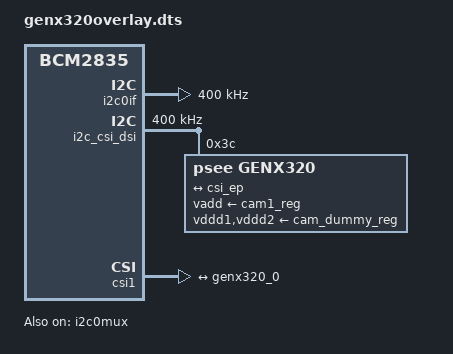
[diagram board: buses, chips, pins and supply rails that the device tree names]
// SPDX-License-Identifier: GPL-2.0-only
// Definitions for GenX320 camera module on VC I2C bus
/dts-v1/;
/plugin/;

// #include <dt-bindings/gpio/gpio.h>

/{
	compatible = "brcm,bcm2835";

	fragment@0 {
		target = <&i2c0if>;
		__overlay__ {
			status = "okay";
			clock-frequency = <400000>;
		};
	};

	clk_frag: fragment@1 {
		target = <&cam1_clk>;
		__overlay__ {
			status = "okay";
			clock-frequency = <20000000>;
		};
	};

	fragment@2 {
		target = <&i2c0mux>;
		__overlay__ {
			status = "okay";
		};
	};

	reg_frag: fragment@5 {
		target = <&cam1_reg>;
		cam_reg: __overlay__ {
			/* 500 ms lets CCAM5 on-module regulators stabilise before
			 * the driver's first I2C access. Increase via dtoverlay
			 * startup-delay-us=<N> if probe still times out. */
			startup-delay-us = <500000>;
		};
	};

	reg_alwayson_frag: fragment@99 {
		target = <&cam1_reg>;
		__dormant__ {
			regulator-always-on;
		};
	};

	i2c_frag: fragment@100 {
		target = <&i2c_csi_dsi>;
		__overlay__ {
			#address-cells = <1>;
			#size-cells = <0>;
			status = "okay";
			clock-frequency = <400000>;
			genx320: genx320@3c {
				compatible = "psee,genx320";
				reg = <0x3c>;
				status = "okay";

				clocks = <&cam1_clk>;
				clock-names = "inclk";

				/* Ask the Linux clock framework to program the RP1
				 * GPCLK to 20 MHz at probe time.  The Pi firmware
				 * already reads clock-frequency above before Linux
				 * boots, but on Pi 5 the RP1 clock driver can reset
				 * the rate unless assigned-clock-rates is also set. */
				assigned-clocks = <&cam1_clk>;
				assigned-clock-rates = <20000000>;

				vadd-supply = <&cam1_reg>;
				vddd1-supply = <&cam_dummy_reg>;
				vddd2-supply = <&cam_dummy_reg>;

				rotation = <180>;
				orientation = <2>;

				rstn-delay-ms = <385>;

				port {
					genx320_0: endpoint {
						remote-endpoint = <&csi_ep>;
						clock-lanes = <0>;
						data-lanes = <1>;
						clock-noncontinuous;
						link-frequencies = /bits/ 64 <750000000>;
					};
				};
			};
		};
	};

	csi_frag: fragment@101 {
		target = <&csi1>;
		csi: __overlay__ {
			status = "okay";
			brcm,media-controller;

			port {
				csi_ep: endpoint {
					remote-endpoint = <&genx320_0>;
					clock-lanes = <0>;
					data-lanes = <1>;
					clock-noncontinuous;
				};
			};
		};
	};

	__overrides__ {
		rotation = <&genx320>,"rotation:0";
		orientation = <&genx320>,"orientation:0";
		media-controller = <&csi>,"brcm,media-controller?";
		cam0 = <&i2c_frag>, "target:0=",<&i2c_csi_dsi0>,
				<&csi_frag>, "target:0=",<&csi0>,
				<&clk_frag>, "target:0=",<&cam0_clk>,
				<&reg_frag>, "target:0=",<&cam0_reg>,
				<&reg_alwayson_frag>, "target:0=",<&cam0_reg>,
				<&genx320>, "clocks:0=",<&cam0_clk>,
				<&genx320>, "assigned-clocks:0=",<&cam0_clk>,
				<&genx320>, "vadd-supply:0=",<&cam0_reg>;
		always-on = <0>, "+99";
		/* Timing knobs: increase if the sensor still doesn't respond.
		 * Example: dtoverlay=genx320,rstn-delay-ms=600,startup-delay-us=800000 */
		rstn-delay-ms    = <&genx320>,"rstn-delay-ms:0";
		startup-delay-us = <&cam_reg>,"startup-delay-us:0";
	};
};
